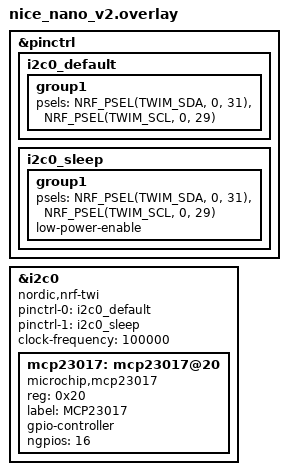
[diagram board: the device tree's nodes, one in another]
/*
 * Copyright (c) 2020 The ZMK Contributors
 *
 * SPDX-License-Identifier: MIT
 * 
 * Nice!Nano v2 overlay for MCP23017 I2C GPIO expander
 */

&pinctrl {
    i2c0_default: i2c0_default {
        group1 {
            psels = <NRF_PSEL(TWIM_SDA, 0, 31)>,
                    <NRF_PSEL(TWIM_SCL, 0, 29)>;
        };
    };

    i2c0_sleep: i2c0_sleep {
        group1 {
            psels = <NRF_PSEL(TWIM_SDA, 0, 31)>,
                    <NRF_PSEL(TWIM_SCL, 0, 29)>;
            low-power-enable;
        };
    };
};

&i2c0 {
    status = "okay";
    compatible = "nordic,nrf-twi";
    pinctrl-0 = <&i2c0_default>;
    pinctrl-1 = <&i2c0_sleep>;
    pinctrl-names = "default", "sleep";
    clock-frequency = <100000>;

    mcp23017: mcp23017@20 {
        compatible = "microchip,mcp23017";
        status = "okay";
        reg = <0x20>;
        label = "MCP23017";
        gpio-controller;
        #gpio-cells = <2>;
        ngpios = <16>;
    };
};
